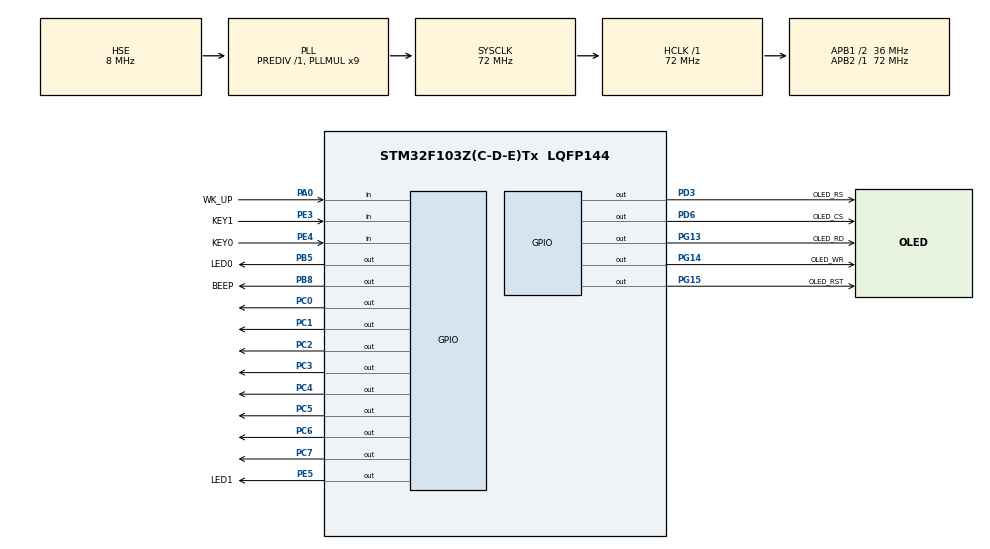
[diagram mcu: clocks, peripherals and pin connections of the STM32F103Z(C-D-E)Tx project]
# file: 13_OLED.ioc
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Mcu.Family=STM32F1
Mcu.Name=STM32F103Z(C-D-E)Tx
Mcu.Package=LQFP144
NVIC.PriorityGroup=NVIC_PRIORITYGROUP_4
OSC_IN.Mode=HSE-External-Oscillator
OSC_IN.Signal=RCC_OSC_IN
OSC_OUT.Mode=HSE-External-Oscillator
OSC_OUT.Signal=RCC_OSC_OUT
PA0-WKUP.GPIO_Label=WK_UP
PA0-WKUP.GPIO_PuPd=GPIO_PULLDOWN
PA0-WKUP.Signal=GPIO_Input
PA13.Mode=Serial_Wire
PA13.Signal=SYS_JTMS-SWDIO
PA14.Mode=Serial_Wire
PA14.Signal=SYS_JTCK-SWCLK
PB5.GPIO_Label=LED0
PB5.GPIO_PuPd=GPIO_PULLUP
PB5.PinState=GPIO_PIN_SET
PB5.Signal=GPIO_Output
PB8.GPIO_Label=BEEP
PB8.GPIO_PuPd=GPIO_PULLDOWN
PB8.PinState=GPIO_PIN_RESET
PB8.Signal=GPIO_Output
PC0.GPIO_PuPd=GPIO_PULLUP
PC0.GPIO_Speed=GPIO_SPEED_FREQ_HIGH
PC0.PinState=GPIO_PIN_SET
PC0.Signal=GPIO_Output
PC1.GPIO_PuPd=GPIO_PULLUP
PC1.GPIO_Speed=GPIO_SPEED_FREQ_HIGH
PC1.PinState=GPIO_PIN_SET
PC1.Signal=GPIO_Output
PC14-OSC32_IN.Mode=LSE-External-Oscillator
PC14-OSC32_IN.Signal=RCC_OSC32_IN
PC15-OSC32_OUT.Mode=LSE-External-Oscillator
PC15-OSC32_OUT.Signal=RCC_OSC32_OUT
PC2.GPIO_PuPd=GPIO_PULLUP
PC2.GPIO_Speed=GPIO_SPEED_FREQ_HIGH
PC2.PinState=GPIO_PIN_SET
PC2.Signal=GPIO_Output
PC3.GPIO_PuPd=GPIO_PULLUP
PC3.GPIO_Speed=GPIO_SPEED_FREQ_HIGH
PC3.PinState=GPIO_PIN_SET
PC3.Signal=GPIO_Output
PC4.GPIO_PuPd=GPIO_PULLUP
PC4.GPIO_Speed=GPIO_SPEED_FREQ_HIGH
PC4.PinState=GPIO_PIN_SET
PC4.Signal=GPIO_Output
PC5.GPIO_PuPd=GPIO_PULLUP
PC5.GPIO_Speed=GPIO_SPEED_FREQ_HIGH
PC5.PinState=GPIO_PIN_SET
PC5.Signal=GPIO_Output
PC6.GPIO_PuPd=GPIO_PULLUP
PC6.GPIO_Speed=GPIO_SPEED_FREQ_HIGH
PC6.PinState=GPIO_PIN_SET
PC6.Signal=GPIO_Output
PC7.GPIO_PuPd=GPIO_PULLUP
PC7.GPIO_Speed=GPIO_SPEED_FREQ_HIGH
PC7.PinState=GPIO_PIN_SET
PC7.Signal=GPIO_Output
PD3.GPIO_Label=OLED_RS
PD3.GPIO_PuPd=GPIO_PULLUP
PD3.GPIO_Speed=GPIO_SPEED_FREQ_HIGH
PD3.PinState=GPIO_PIN_SET
PD3.Signal=GPIO_Output
PD6.GPIO_Label=OLED_CS
PD6.GPIO_PuPd=GPIO_PULLUP
PD6.GPIO_Speed=GPIO_SPEED_FREQ_HIGH
PD6.PinState=GPIO_PIN_SET
PD6.Signal=GPIO_Output
PE3.GPIO_Label=KEY1
PE3.GPIO_PuPd=GPIO_PULLUP
PE3.Signal=GPIO_Input
PE4.GPIO_Label=KEY0
PE4.GPIO_PuPd=GPIO_PULLUP
PE4.Signal=GPIO_Input
PE5.GPIO_Label=LED1
PE5.GPIO_PuPd=GPIO_PULLUP
PE5.PinState=GPIO_PIN_SET
PE5.Signal=GPIO_Output
PG13.GPIO_Label=OLED_RD
PG13.GPIO_PuPd=GPIO_PULLUP
PG13.GPIO_Speed=GPIO_SPEED_FREQ_HIGH
PG13.PinState=GPIO_PIN_SET
PG13.Signal=GPIO_Output
PG14.GPIO_Label=OLED_WR
PG14.GPIO_PuPd=GPIO_PULLUP
PG14.GPIO_Speed=GPIO_SPEED_FREQ_HIGH
PG14.PinState=GPIO_PIN_SET
PG14.Signal=GPIO_Output
PG15.GPIO_Label=OLED_RST
PG15.GPIO_PuPd=GPIO_PULLUP
PG15.GPIO_Speed=GPIO_SPEED_FREQ_HIGH
PG15.PinState=GPIO_PIN_SET
PG15.Signal=GPIO_Output
ProjectManager.HeapSize=0x200
ProjectManager.StackSize=0x400
ProjectManager.TargetToolchain=STM32CubeIDE
RCC.AHBFreq_Value=72000000
RCC.APB1CLKDivider=RCC_HCLK_DIV2
RCC.APB1Freq_Value=36000000
RCC.APB1TimFreq_Value=72000000
RCC.APB2Freq_Value=72000000
RCC.APB2TimFreq_Value=72000000
RCC.HCLKFreq_Value=72000000
RCC.PLLMUL=RCC_PLL_MUL9
RCC.PLLSourceVirtual=RCC_PLLSOURCE_HSE
RCC.SYSCLKFreq_VALUE=72000000
RCC.SYSCLKSource=RCC_SYSCLKSOURCE_PLLCLK
RCC.USBFreq_Value=72000000
board=custom

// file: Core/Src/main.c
/* USER CODE BEGIN Header */
/**
  ******************************************************************************
  * @file           : main.c
  * @brief          : Main program body
  ******************************************************************************
  * @attention
  *
  * Copyright (c) 2023 STMicroelectronics.
  * All rights reserved.
  *
  * This software is licensed under terms that can be found in the LICENSE file
  * in the root directory of this software component.
  * If no LICENSE file comes with this software, it is provided AS-IS.
  *
  ******************************************************************************
  */
/* USER CODE END Header */
#include "main.h"
#include "gpio.h"

/* USER CODE BEGIN Includes */
#include "../../BSP/LED/led.h"
#include "../../BSP/BEEP/beep.h"
#include "../../BSP/KEY/key.h"
#include "../../BSP/OLED/oled.h"
/* USER CODE END Includes */

void SystemClock_Config(void);

int main(void)
{

  /* MCU Configuration--------------------------------------------------------*/

  /* Reset of all peripherals, Initializes the Flash interface and the Systick. */
  HAL_Init();

  /* Configure the system clock */
  SystemClock_Config();

  /* Initialize all configured peripherals */
  MX_GPIO_Init();
  /* USER CODE BEGIN 2 */
  oled_init();
//  oled_clear();
//  oled_test();
//  oled_draw_point(128/2, 64/2, 1);
//  oled_refresh_gram();

  oled_show_string(0, 0, "yyds", 12);
  show_str(0 , 30, "����ԭ�������", 16, &font_16x16_mis, 1);
  oled_draw_bitmap(50, 0, (uint8_t *)&wendu_32x32_logo, 32, 32, 1);
  oled_refresh_gram();
  /* USER CODE END 2 */

  /* Infinite loop */
  /* USER CODE BEGIN WHILE */
  while (1)
  {
//	  for(uint8_t i = 0; i < 64; i++)
//	  {
//		  oled_clear();
//		  oled_draw_point(2*i, i, 1);
//		  oled_refresh_gram();
//		  HAL_Delay(10);
//	  }
    /* USER CODE END WHILE */

  }
}

void SystemClock_Config(void)
{
  RCC_OscInitTypeDef RCC_OscInitStruct = {0};
  RCC_ClkInitTypeDef RCC_ClkInitStruct = {0};

  /** Initializes the RCC Oscillators according to the specified parameters
  * in the RCC_OscInitTypeDef structure.
  */
  RCC_OscInitStruct.OscillatorType = RCC_OSCILLATORTYPE_HSE;
  RCC_OscInitStruct.HSEState = RCC_HSE_ON;
  RCC_OscInitStruct.HSEPredivValue = RCC_HSE_PREDIV_DIV1;
  RCC_OscInitStruct.HSIState = RCC_HSI_ON;
  RCC_OscInitStruct.PLL.PLLState = RCC_PLL_ON;
  RCC_OscInitStruct.PLL.PLLSource = RCC_PLLSOURCE_HSE;
  RCC_OscInitStruct.PLL.PLLMUL = RCC_PLL_MUL9;
  if (HAL_RCC_OscConfig(&RCC_OscInitStruct) != HAL_OK)
  {
    Error_Handler();
  }

  /** Initializes the CPU, AHB and APB buses clocks
  */
  RCC_ClkInitStruct.ClockType = RCC_CLOCKTYPE_HCLK|RCC_CLOCKTYPE_SYSCLK
                              |RCC_CLOCKTYPE_PCLK1|RCC_CLOCKTYPE_PCLK2;
  RCC_ClkInitStruct.SYSCLKSource = RCC_SYSCLKSOURCE_PLLCLK;
  RCC_ClkInitStruct.AHBCLKDivider = RCC_SYSCLK_DIV1;
  RCC_ClkInitStruct.APB1CLKDivider = RCC_HCLK_DIV2;
  RCC_ClkInitStruct.APB2CLKDivider = RCC_HCLK_DIV1;

  if (HAL_RCC_ClockConfig(&RCC_ClkInitStruct, FLASH_LATENCY_2) != HAL_OK)
  {
    Error_Handler();
  }
}

void Error_Handler(void)
{
  __disable_irq();
  while (1)
  {
  }
}
